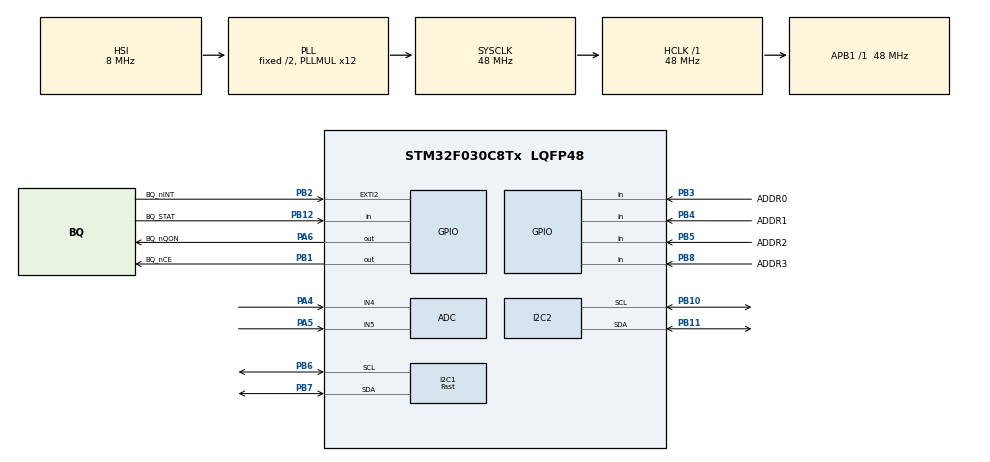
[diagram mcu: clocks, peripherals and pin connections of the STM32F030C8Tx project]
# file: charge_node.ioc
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ADC.SamplingTime=ADC_SAMPLETIME_239CYCLES_5
I2C1.I2C_Speed_Mode=I2C_Fast
I2C1.OwnAddress=0x20
I2C1.Timing=0x0090194B
I2C2.Timing=0x10805D88
Mcu.Family=STM32F0
Mcu.Name=STM32F030C8Tx
Mcu.Package=LQFP48
NVIC.EXTI2_3_IRQn=true\:0\:0\:false\:false\:true\:true\:true\:true
NVIC.I2C1_IRQn=true\:0\:0\:false\:false\:true\:true\:true\:true
PA13.Mode=Serial_Wire
PA13.Signal=SYS_SWDIO
PA14.Mode=Serial_Wire
PA14.Signal=SYS_SWCLK
PA4.Mode=IN4
PA4.Signal=ADC_IN4
PA5.Mode=IN5
PA5.Signal=ADC_IN5
PA6.GPIO_Label=BQ_nQON
PA6.PinState=GPIO_PIN_SET
PA6.Signal=GPIO_Output
PB1.GPIO_Label=BQ_nCE
PB1.PinState=GPIO_PIN_SET
PB1.Signal=GPIO_Output
PB10.Mode=I2C
PB10.Signal=I2C2_SCL
PB11.Mode=I2C
PB11.Signal=I2C2_SDA
PB12.GPIO_Label=BQ_STAT
PB12.Signal=GPIO_Input
PB2.GPIO_Label=BQ_nINT
PB2.GPIO_ModeDefaultEXTI=GPIO_MODE_IT_FALLING
PB2.Signal=GPXTI2
PB3.GPIO_Label=ADDR0
PB3.GPIO_PuPd=GPIO_PULLUP
PB3.Signal=GPIO_Input
PB4.GPIO_Label=ADDR1
PB4.GPIO_PuPd=GPIO_PULLUP
PB4.Signal=GPIO_Input
PB5.GPIO_Label=ADDR2
PB5.GPIO_PuPd=GPIO_PULLUP
PB5.Signal=GPIO_Input
PB6.Mode=I2C
PB6.Signal=I2C1_SCL
PB7.Mode=I2C
PB7.Signal=I2C1_SDA
PB8.GPIO_Label=ADDR3
PB8.GPIO_PuPd=GPIO_PULLUP
PB8.Signal=GPIO_Input
ProjectManager.HeapSize=0x200
ProjectManager.StackSize=0x400
ProjectManager.TargetToolchain=EWARM V8
RCC.AHBFreq_Value=48000000
RCC.APB1Freq_Value=48000000
RCC.APB1TimFreq_Value=48000000
RCC.HCLKFreq_Value=48000000
RCC.I2c1ClockSelection=RCC_I2C1CLKSOURCE_SYSCLK
RCC.PLLMUL=RCC_PLL_MUL12
RCC.SYSCLKFreq_VALUE=48000000
RCC.SYSCLKSource=RCC_SYSCLKSOURCE_PLLCLK
board=custom

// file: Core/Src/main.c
/* USER CODE BEGIN Header */
/**
  ******************************************************************************
  * @file           : main.c
  * @brief          : Main program body
  ******************************************************************************
  * @attention
  *
  * Copyright (c) 2026 STMicroelectronics.
  * All rights reserved.
  *
  * This software is licensed under terms that can be found in the LICENSE file
  * in the root directory of this software component.
  * If no LICENSE file comes with this software, it is provided AS-IS.
  *
  ******************************************************************************
  */
/* USER CODE END Header */
#include "main.h"

ADC_HandleTypeDef hadc;

I2C_HandleTypeDef hi2c1;
I2C_HandleTypeDef hi2c2;

void SystemClock_Config(void);
static void MX_GPIO_Init(void);
static void MX_ADC_Init(void);
static void MX_I2C1_Init(void);
static void MX_I2C2_Init(void);

int main(void)
{

  /* MCU Configuration--------------------------------------------------------*/

  /* Reset of all peripherals, Initializes the Flash interface and the Systick. */
  HAL_Init();

  /* Configure the system clock */
  SystemClock_Config();

  /* Initialize all configured peripherals */
  MX_GPIO_Init();
  MX_ADC_Init();
  MX_I2C1_Init();
  MX_I2C2_Init();

  /* Infinite loop */
  while (1)
  {

  }
}

void SystemClock_Config(void)
{
  RCC_OscInitTypeDef RCC_OscInitStruct = {0};
  RCC_ClkInitTypeDef RCC_ClkInitStruct = {0};
  RCC_PeriphCLKInitTypeDef PeriphClkInit = {0};

  /** Initializes the RCC Oscillators according to the specified parameters
  * in the RCC_OscInitTypeDef structure.
  */
  RCC_OscInitStruct.OscillatorType = RCC_OSCILLATORTYPE_HSI|RCC_OSCILLATORTYPE_HSI14;
  RCC_OscInitStruct.HSIState = RCC_HSI_ON;
  RCC_OscInitStruct.HSI14State = RCC_HSI14_ON;
  RCC_OscInitStruct.HSICalibrationValue = RCC_HSICALIBRATION_DEFAULT;
  RCC_OscInitStruct.HSI14CalibrationValue = 16;
  RCC_OscInitStruct.PLL.PLLState = RCC_PLL_ON;
  RCC_OscInitStruct.PLL.PLLSource = RCC_PLLSOURCE_HSI;
  RCC_OscInitStruct.PLL.PLLMUL = RCC_PLL_MUL12;
  RCC_OscInitStruct.PLL.PREDIV = RCC_PREDIV_DIV1;
  if (HAL_RCC_OscConfig(&RCC_OscInitStruct) != HAL_OK)
  {
    Error_Handler();
  }

  /** Initializes the CPU, AHB and APB buses clocks
  */
  RCC_ClkInitStruct.ClockType = RCC_CLOCKTYPE_HCLK|RCC_CLOCKTYPE_SYSCLK
                              |RCC_CLOCKTYPE_PCLK1;
  RCC_ClkInitStruct.SYSCLKSource = RCC_SYSCLKSOURCE_PLLCLK;
  RCC_ClkInitStruct.AHBCLKDivider = RCC_SYSCLK_DIV1;
  RCC_ClkInitStruct.APB1CLKDivider = RCC_HCLK_DIV1;

  if (HAL_RCC_ClockConfig(&RCC_ClkInitStruct, FLASH_LATENCY_1) != HAL_OK)
  {
    Error_Handler();
  }
  PeriphClkInit.PeriphClockSelection = RCC_PERIPHCLK_I2C1;
  PeriphClkInit.I2c1ClockSelection = RCC_I2C1CLKSOURCE_SYSCLK;
  if (HAL_RCCEx_PeriphCLKConfig(&PeriphClkInit) != HAL_OK)
  {
    Error_Handler();
  }
}

static void MX_ADC_Init(void)
{

  ADC_ChannelConfTypeDef sConfig = {0};

  /** Configure the global features of the ADC (Clock, Resolution, Data Alignment and number of conversion)
  */
  hadc.Instance = ADC1;
  hadc.Init.ClockPrescaler = ADC_CLOCK_ASYNC_DIV1;
  hadc.Init.Resolution = ADC_RESOLUTION_12B;
  hadc.Init.DataAlign = ADC_DATAALIGN_RIGHT;
  hadc.Init.ScanConvMode = ADC_SCAN_DIRECTION_FORWARD;
  hadc.Init.EOCSelection = ADC_EOC_SINGLE_CONV;
  hadc.Init.LowPowerAutoWait = DISABLE;
  hadc.Init.LowPowerAutoPowerOff = DISABLE;
  hadc.Init.ContinuousConvMode = DISABLE;
  hadc.Init.DiscontinuousConvMode = DISABLE;
  hadc.Init.ExternalTrigConv = ADC_SOFTWARE_START;
  hadc.Init.ExternalTrigConvEdge = ADC_EXTERNALTRIGCONVEDGE_NONE;
  hadc.Init.DMAContinuousRequests = DISABLE;
  hadc.Init.Overrun = ADC_OVR_DATA_PRESERVED;
  if (HAL_ADC_Init(&hadc) != HAL_OK)
  {
    Error_Handler();
  }

  /** Configure for the selected ADC regular channel to be converted.
  */
  sConfig.Channel = ADC_CHANNEL_4;
  sConfig.Rank = ADC_RANK_CHANNEL_NUMBER;
  sConfig.SamplingTime = ADC_SAMPLETIME_239CYCLES_5;
  if (HAL_ADC_ConfigChannel(&hadc, &sConfig) != HAL_OK)
  {
    Error_Handler();
  }

  /** Configure for the selected ADC regular channel to be converted.
  */
  sConfig.Channel = ADC_CHANNEL_5;
  if (HAL_ADC_ConfigChannel(&hadc, &sConfig) != HAL_OK)
  {
    Error_Handler();
  }

}

static void MX_I2C1_Init(void)
{

  /* USER CODE BEGIN I2C1_Init 0 */
  uint8_t addr;

  /* USER CODE END I2C1_Init 0 */

  hi2c1.Instance = I2C1;
  hi2c1.Init.Timing = 0x0090194B;
  hi2c1.Init.OwnAddress1 = 64;
  hi2c1.Init.AddressingMode = I2C_ADDRESSINGMODE_7BIT;
  hi2c1.Init.DualAddressMode = I2C_DUALADDRESS_DISABLE;
  hi2c1.Init.OwnAddress2 = 0;
  hi2c1.Init.OwnAddress2Masks = I2C_OA2_NOMASK;
  hi2c1.Init.GeneralCallMode = I2C_GENERALCALL_DISABLE;
  hi2c1.Init.NoStretchMode = I2C_NOSTRETCH_DISABLE;
  if (HAL_I2C_Init(&hi2c1) != HAL_OK)
  {
    Error_Handler();
  }

  /** Configure Analogue filter
  */
  if (HAL_I2CEx_ConfigAnalogFilter(&hi2c1, I2C_ANALOGFILTER_ENABLE) != HAL_OK)
  {
    Error_Handler();
  }

  /** Configure Digital filter
  */
  if (HAL_I2CEx_ConfigDigitalFilter(&hi2c1, 0) != HAL_OK)
  {
    Error_Handler();
  }
  /* USER CODE BEGIN I2C1_Init 2 */
  /* Sample ADDRx pins */
  addr  = ((HAL_GPIO_ReadPin(ADDR0_GPIO_Port, ADDR0_Pin) == GPIO_PIN_SET) ?
    0x01 : 0);
  addr |= ((HAL_GPIO_ReadPin(ADDR1_GPIO_Port, ADDR1_Pin) == GPIO_PIN_SET) ?
    0x02 : 0);
  addr |= ((HAL_GPIO_ReadPin(ADDR2_GPIO_Port, ADDR2_Pin) == GPIO_PIN_SET) ?
    0x04 : 0);
  addr |= ((HAL_GPIO_ReadPin(ADDR3_GPIO_Port, ADDR3_Pin) == GPIO_PIN_SET) ?
    0x08 : 0);

  /* Update own address */
  hi2c1.Init.OwnAddress1 = hi2c1.Init.OwnAddress1 + (addr << 1);
  hi2c1.Instance->OAR1 &= ~I2C_OAR1_OA1EN;
  hi2c1.Instance->OAR1  = (I2C_OAR1_OA1EN | hi2c1.Init.OwnAddress1);

  /* USER CODE END I2C1_Init 2 */

}

static void MX_I2C2_Init(void)
{

  hi2c2.Instance = I2C2;
  hi2c2.Init.Timing = 0x10805D88;
  hi2c2.Init.OwnAddress1 = 0;
  hi2c2.Init.AddressingMode = I2C_ADDRESSINGMODE_7BIT;
  hi2c2.Init.DualAddressMode = I2C_DUALADDRESS_DISABLE;
  hi2c2.Init.OwnAddress2 = 0;
  hi2c2.Init.OwnAddress2Masks = I2C_OA2_NOMASK;
  hi2c2.Init.GeneralCallMode = I2C_GENERALCALL_DISABLE;
  hi2c2.Init.NoStretchMode = I2C_NOSTRETCH_DISABLE;
  if (HAL_I2C_Init(&hi2c2) != HAL_OK)
  {
    Error_Handler();
  }

  /** Configure Analogue filter
  */
  if (HAL_I2CEx_ConfigAnalogFilter(&hi2c2, I2C_ANALOGFILTER_ENABLE) != HAL_OK)
  {
    Error_Handler();
  }

  /** Configure Digital filter
  */
  if (HAL_I2CEx_ConfigDigitalFilter(&hi2c2, 0) != HAL_OK)
  {
    Error_Handler();
  }

}

static void MX_GPIO_Init(void)
{
  GPIO_InitTypeDef GPIO_InitStruct = {0};

  /* GPIO Ports Clock Enable */
  __HAL_RCC_GPIOA_CLK_ENABLE();
  __HAL_RCC_GPIOB_CLK_ENABLE();

  /*Configure GPIO pin Output Level */
  HAL_GPIO_WritePin(BQ_nQON_GPIO_Port, BQ_nQON_Pin, GPIO_PIN_SET);

  /*Configure GPIO pin Output Level */
  HAL_GPIO_WritePin(BQ_nCE_GPIO_Port, BQ_nCE_Pin, GPIO_PIN_SET);

  /*Configure GPIO pin : BQ_nQON_Pin */
  GPIO_InitStruct.Pin = BQ_nQON_Pin;
  GPIO_InitStruct.Mode = GPIO_MODE_OUTPUT_PP;
  GPIO_InitStruct.Pull = GPIO_NOPULL;
  GPIO_InitStruct.Speed = GPIO_SPEED_FREQ_LOW;
  HAL_GPIO_Init(BQ_nQON_GPIO_Port, &GPIO_InitStruct);

  /*Configure GPIO pin : BQ_nCE_Pin */
  GPIO_InitStruct.Pin = BQ_nCE_Pin;
  GPIO_InitStruct.Mode = GPIO_MODE_OUTPUT_PP;
  GPIO_InitStruct.Pull = GPIO_NOPULL;
  GPIO_InitStruct.Speed = GPIO_SPEED_FREQ_LOW;
  HAL_GPIO_Init(BQ_nCE_GPIO_Port, &GPIO_InitStruct);

  /*Configure GPIO pin : BQ_nINT_Pin */
  GPIO_InitStruct.Pin = BQ_nINT_Pin;
  GPIO_InitStruct.Mode = GPIO_MODE_IT_FALLING;
  GPIO_InitStruct.Pull = GPIO_NOPULL;
  HAL_GPIO_Init(BQ_nINT_GPIO_Port, &GPIO_InitStruct);

  /*Configure GPIO pin : BQ_STAT_Pin */
  GPIO_InitStruct.Pin = BQ_STAT_Pin;
  GPIO_InitStruct.Mode = GPIO_MODE_INPUT;
  GPIO_InitStruct.Pull = GPIO_NOPULL;
  HAL_GPIO_Init(BQ_STAT_GPIO_Port, &GPIO_InitStruct);

  /*Configure GPIO pins : ADDR0_Pin ADDR1_Pin ADDR2_Pin ADDR3_Pin */
  GPIO_InitStruct.Pin = ADDR0_Pin|ADDR1_Pin|ADDR2_Pin|ADDR3_Pin;
  GPIO_InitStruct.Mode = GPIO_MODE_INPUT;
  GPIO_InitStruct.Pull = GPIO_PULLUP;
  HAL_GPIO_Init(GPIOB, &GPIO_InitStruct);

  /* EXTI interrupt init*/
  HAL_NVIC_SetPriority(EXTI2_3_IRQn, 0, 0);
  HAL_NVIC_EnableIRQ(EXTI2_3_IRQn);

}

void Error_Handler(void)
{
  __disable_irq();
  while (1)
  {
  }
}
